# EMIF register map
Vendor: Texas Instruments
Registers are 32-bit, access per field, no defined reset value unless marked. A register's access mark holds for its fields unless they carry their own. Offsets are as the file gives them; [hi:lo] are bit positions; {n}, {i} and the like mark numbered series; 'fields as' and 'values as' point back to an identical list.

## EMIF (part 2 of 2)
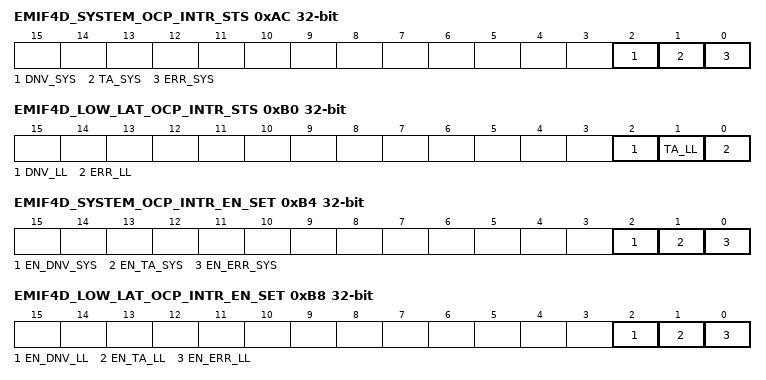
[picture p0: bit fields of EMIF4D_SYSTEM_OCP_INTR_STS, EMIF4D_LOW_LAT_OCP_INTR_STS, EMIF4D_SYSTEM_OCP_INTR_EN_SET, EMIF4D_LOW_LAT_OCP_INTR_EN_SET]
0xAC EMIF4D_SYSTEM_OCP_INTR_STS
  [2] DNV_SYS rw — Enabled status of system OCP interrupt for LPDDR2 NVM data not valid. [[br]]Write 1 to clear the status after interrupt has been serviced (raw status gets cleared, i.e. [[br]]even if not enabled). [[br]]Writing a 0 has no effect.
  [1] TA_SYS rw — Enabled status of system OCP interrupt for SDRAM temperature alert. [[br]]Write 1 to clear the status after interrupt has been serviced (raw status gets cleared, i.e. [[br]]even if not enabled). [[br]]Writing a 0 has no effect.
  [0] ERR_SYS rw — Enabled status of system OCP interrupt for command and address error. [[br]]Write 1 to clear the status after interrupt has been serviced (raw status gets cleared, i.e. [[br]]even if not enabled). [[br]]Writing a 0 has no effect.
0xB0 EMIF4D_LOW_LAT_OCP_INTR_STS
  [2] DNV_LL rw — Enabled status of low-latency OCP interrupt for LPDDR2 NVM data not valid. [[br]]Write 1 to clear the status after interrupt has been serviced (raw status gets cleared, i.e. [[br]]even if not enabled). [[br]]Writing a 0 has no effect.
  [1] TA_LL rw — Enabled status of low-latency OCP interrupt for SDRAM temperature alert. [[br]]Write 1 to clear the status after interrupt has been serviced (raw status gets cleared, i.e. [[br]]even if not enabled). [[br]]Writing a 0 has no effect.
  [0] ERR_LL rw — Enabled status of low-latency OCP interrupt for command and address error. [[br]]Write 1 to clear the status after interrupt has been serviced (raw status gets cleared, i.e. [[br]]even if not enabled). [[br]]Writing a 0 has no effect.
0xB4 EMIF4D_SYSTEM_OCP_INTR_EN_SET
  [2] EN_DNV_SYS rw — Enable set for system OCP interrupt for LPDDR2 NVM data not valid. [[br]]Writing a 1 will enable the interrupt, and set this bit as well as the corresponding Interrupt Enable Clear Register. [[br]]Writing a 0 has no effect.
  [1] EN_TA_SYS rw — Enable set for system OCP interrupt for SDRAM temperature alert. [[br]]Writing a 1 will enable the interrupt, and set this bit as well as the corresponding Interrupt Enable Clear Register. [[br]]Writing a 0 has no effect.
  [0] EN_ERR_SYS rw — Enable set for system OCP interrupt for command and address error. [[br]]Writing a 1 will enable the interrupt, and set this bit as well as the corresponding Interrupt Enable Clear Register. [[br]]Writing a 0 has no effect.
0xB8 EMIF4D_LOW_LAT_OCP_INTR_EN_SET
  [2] EN_DNV_LL rw — Enable set for low-latency OCP interrupt for LPDDR2 NVM data not valid. [[br]]Writing a 1 will enable the interrupt, and set this bit as well as the corresponding Interrupt Enable Clear Register. [[br]]Writing a 0 has no effect.
  [1] EN_TA_LL rw — Enable set for low-latency OCP interrupt for SDRAM temperature alert. [[br]]Writing a 1 will enable the interrupt, and set this bit as well as the corresponding Interrupt Enable Clear Register. [[br]]Writing a 0 has no effect.
  [0] EN_ERR_LL rw — Enable set for low-latency OCP interrupt for command and address error. [[br]]Writing a 1 will enable the interrupt, and set this bit as well as the corresponding Interrupt Enable Clear Register. [[br]]Writing a 0 has no effect.
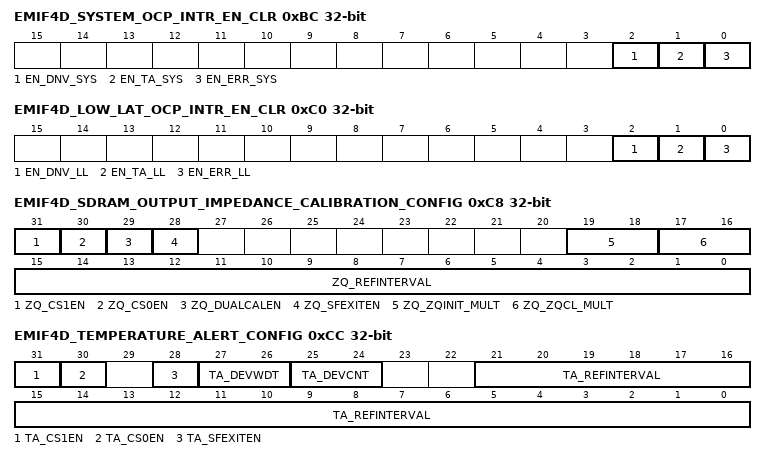
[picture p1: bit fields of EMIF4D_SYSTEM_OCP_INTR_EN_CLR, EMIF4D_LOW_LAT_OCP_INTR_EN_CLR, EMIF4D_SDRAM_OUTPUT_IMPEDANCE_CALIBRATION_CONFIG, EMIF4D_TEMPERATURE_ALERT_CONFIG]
0xBC EMIF4D_SYSTEM_OCP_INTR_EN_CLR
  [2] EN_DNV_SYS rw — Enable clear for system OCP interrupt for LPDDR2 NVM data not valid. [[br]]Writing a 1 will disable the interrupt, and clear this bit as well as the corresponding Interrupt Enable Set Register. [[br]]Writing a 0 has no effect.
  [1] EN_TA_SYS rw — Enable clear for system OCP interrupt for SDRAM temperature alert. [[br]]Writing a 1 will disable the interrupt, and clear this bit as well as the corresponding Interrupt Enable Set Register. [[br]]Writing a 0 has no effect.
  [0] EN_ERR_SYS rw — Enable clear for system OCP interrupt for command and address error. [[br]]Writing a 1 will disable the interrupt, and clear this bit as well as the corresponding Interrupt Enable Set Register. [[br]]Writing a 0 has no effect.
0xC0 EMIF4D_LOW_LAT_OCP_INTR_EN_CLR
  [2] EN_DNV_LL rw — Enable clear for low-latency OCP interrupt for LPDDR2 NVM data not valid. [[br]]Writing a 1 will disable the interrupt, and clear this bit as well as the corresponding Interrupt Enable Set Register. [[br]]Writing a 0 has no effect.
  [1] EN_TA_LL rw — Enable clear for low-latency OCP interrupt for SDRAM temperature alert. [[br]]Writing a 1 will disable the interrupt, and clear this bit as well as the corresponding Interrupt Enable Set Register. [[br]]Writing a 0 has no effect.
  [0] EN_ERR_LL rw — Enable clear for low-latency OCP interrupt for command and address error. [[br]]Writing a 1 will disable the interrupt, and clear this bit as well as the corresponding Interrupt Enable Set Register. [[br]]Writing a 0 has no effect.
0xC8 EMIF4D_SDRAM_OUTPUT_IMPEDANCE_CALIBRATION_CONFIG
  [31] ZQ_CS1EN rw — Writing a 1 enables ZQ calibration for CS1.
  [30] ZQ_CS0EN rw — Writing a 1 enables ZQ calibration for CS0.
  [29] ZQ_DUALCALEN rw — ZQ Dual Calibration enable. [[br]]Allows both ranks to be ZQ calibrated simultaneously. [[br]]Setting this bit requires both chip selects to have a seerate calibration resistor per device.
  [28] ZQ_SFEXITEN rw — ZQCL on Self Refresh, Active Power-Down, and Precharge Power-Down exit enable. [[br]]Writing a 1 enables the issuing of ZQCL on Self-Refresh, Active Power-Down, and Precharge Power-Down exit.
  [19:18] ZQ_ZQINIT_MULT rw — Indicates the number of ZQCL intervals that make up a ZQINIT interval, minus one.
  [17:16] ZQ_ZQCL_MULT rw — Indicates the number of ZQCS intervals that make up a ZQCL interval, minus one. [[br]]ZQCS interval is defined by reg_zq_zqcs in SDRAM Timing 3 Register.
  [15:0] ZQ_REFINTERVAL rw — Number of refresh periods between ZQCS commands. [[br]]This field supports between one refresh period to 256 ms between ZQCS calibration commands. [[br]]Refresh period is defined by reg_refresh_rate in SDRAM Refresh Control register.
0xCC EMIF4D_TEMPERATURE_ALERT_CONFIG
  [31] TA_CS1EN rw — Writing a 1 enables temperature alert polling for CS1.
  [30] TA_CS0EN rw — Writing a 1 enables temperature alert polling for CS0.
  [28] TA_SFEXITEN rw — Temperature Alert Poll on Self-Refresh, Active Power-Down, and Precharge Power-Down exit enable. [[br]]Writing a 1 enables the issuing of a temperature alert poll on Self-Refresh exit.
  [27:26] TA_DEVWDT rw — This field indicates how wide a physical device is. [[br]]It is used in conjunction with the reg_ta_devcnt register to determine which byte lanes contain the tempetature alert info. [[br]]A value of [[br]]0 = eight bit wide, [[br]]1 = sixteen bit wide, [[br]]2 = thirty two bit wide. [[br]]All others are reserved. [[br]]If this field is set to 1 and the reg_ta_devcnt field is set to one the byte mask for checking will be 4'b0101.
  [25:24] TA_DEVCNT rw — This field indicates which external byte lanes contain a device for temperature monitoring. [[br]]A value of [[br]]0 = one device, [[br]]1 = two devices, [[br]]2 = four devices. [[br]]All other reserved.
  [21:0] TA_REFINTERVAL rw — Number of refresh periods between temperature alert polls. [[br]]This field supports one refresh period to 10 seconds between temperature alert polls. [[br]]Refresh period is defined by reg_refresh_rate in SDRAM Refresh Control register.
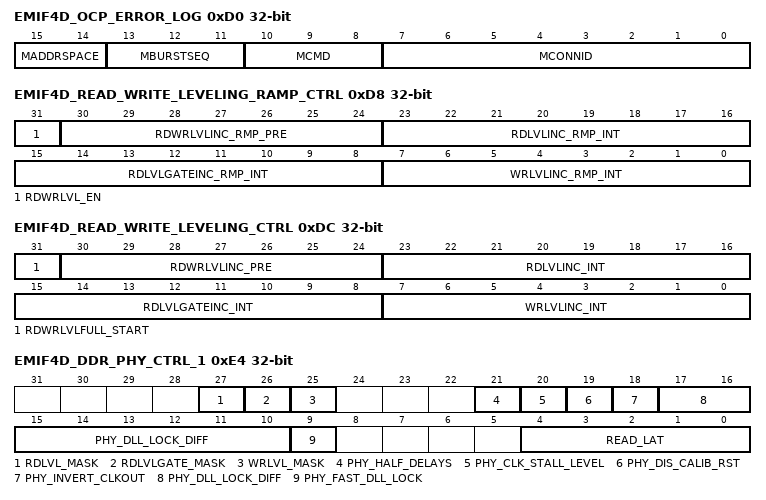
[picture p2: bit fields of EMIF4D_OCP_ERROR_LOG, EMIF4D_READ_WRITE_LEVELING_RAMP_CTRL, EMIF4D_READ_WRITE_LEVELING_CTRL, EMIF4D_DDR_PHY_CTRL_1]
0xD0 EMIF4D_OCP_ERROR_LOG ro
  [15:14] MADDRSPACE — Address space of the first errored transaction. [[br]]Writing a 1 to the lt field in the Interrupt Raw register or the lt_masked field in the Interrupt Masked register will clear this field.
  [13:11] MBURSTSEQ — Addressing mode of the first errored transaction. [[br]]Writing a 1 to the lt field in the Interrupt Raw register or the lt_masked field in the Interrupt Masked register will clear this field.
  [10:8] MCMD — Command type of the first errored transaction. [[br]]Writing a 1 to the lt field in the Interrupt Raw register or the lt_masked field in the Interrupt Masked register will clear this field.
  [7:0] MCONNID — Connection ID of the first errored transaction. [[br]]Writing a 1 to the lt field in the Interrupt Raw register or the lt_masked field in the Interrupt Masked register will clear this field.
0xD4 EMIF4D_READ_WRITE_LEVELING_RAMP_WINDOW
  [12:0] RDWRLVLINC_RMP_WIN rw — Incremental leveling ramp window in number of refresh periods. [[br]]The value programmed is minus one the required value. [[br]]Refresh period is defined by reg_refresh_rate in SDRAM Refresh Control register.
0xD8 EMIF4D_READ_WRITE_LEVELING_RAMP_CTRL rw
  [31] RDWRLVL_EN — Read-Write Leveling enable. [[br]]Set 1 to enable leveling. [[br]]Set 0 to disable leveling.
  [30:24] RDWRLVLINC_RMP_PRE — Incremental leveling pre-scalar in number of refresh periods during ramp window. [[br]]The value programmed is minus one the required value. [[br]]Refresh period is defined by reg_refresh_rate in SDRAM Refresh Control register.
  [23:16] RDLVLINC_RMP_INT — Incremental read data eye training interval during ramp window. [[br]]Number of reg_rdwrlvlinc_rmp_pre intervals between incremental read data eye training during ramp window. [[br]]A value of 0 will disable incremental read data eye training.
  [15:8] RDLVLGATEINC_RMP_INT — Incremental read DQS gate training interval during ramp window. [[br]]Number of reg_rdwrlvlinc_rmp_pre intervals between incremental read DQS gate training during ramp window. [[br]]A value of 0 will disable incremental read DQS gate training.
  [7:0] WRLVLINC_RMP_INT — Incremental write leveling interval during ramp window. [[br]]Number of reg_rdwrlvlinc_rmp_pre intervals between incremental write leveling during ramp window. [[br]]A value of 0 will disable incremental write leveling.
0xDC EMIF4D_READ_WRITE_LEVELING_CTRL rw
  [31] RDWRLVLFULL_START — Full leveling trigger. [[br]]Writing a 1 to this field triggers full read and write leveling. [[br]]This bit will self clear to 0.
  [30:24] RDWRLVLINC_PRE — Incremental leveling pre-scalar in number of refresh periods. [[br]]The value programmed is minus one the required value. [[br]]Refresh period is defined by reg_refresh_rate in SDRAM Refresh Control register.
  [23:16] RDLVLINC_INT — Incremental read data eye training interval. [[br]]Number of reg_rdwrlvlinc_pre intervals between incremental read data eye training. [[br]]A value of 0 will disable incremental read data eye training.
  [15:8] RDLVLGATEINC_INT — Incremental read DQS gate training interval. [[br]]Number of reg_rdwrlvlinc_pre intervals between incremental read DQS gate training. [[br]]A value of 0 will disable incremental read DQS gate training.
  [7:0] WRLVLINC_INT — Incremental write leveling interval. [[br]]Number of reg_rdwrlvlinc_pre intervals between incremental write leveling. [[br]]A value of 0 will disable incremental write leveling.
0xE4 EMIF4D_DDR_PHY_CTRL_1
  [27] RDLVL_MASK rw — writing a 1 to this field will mask read data eye training during full leveling command, plus drives reg_phy_use_rd_data_eye_level control low to allow user to use programmed ratio values. [[br]]Incremental training needs to be disabled using incremental training registers.
  [26] RDLVLGATE_MASK rw — writing a 1 to this field will mask dqs gate training during full leveling command, plus drives reg_phy_use_rd_dqs_level control low to allow user to use programmed ratio values. [[br]]Incremental training needs to be disabled using incremental training registers.
  [25] WRLVL_MASK rw — writing a 1 to this field will mask write leveling training during full leveling command, plus drives reg_phy_use_wr_level control low to allow user to use programmed ratio values. [[br]]Incremental training needs to be disabled using incremental training registers.
  [21] PHY_HALF_DELAYS rw — see phy spec for description
  [20] PHY_CLK_STALL_LEVEL rw — see phy spec for description
  [19] PHY_DIS_CALIB_RST rw — see phy spec for description
  [18] PHY_INVERT_CLKOUT rw — see phy spec for description
  [17:10] PHY_DLL_LOCK_DIFF rw — see phy spec for description
  [9] PHY_FAST_DLL_LOCK rw — see phy spec for description
  [4:0] READ_LAT rw — This field defines the read latency for the read data from SDRAM in number of DDR clock cycles. [[br]]This field is used by the EMIF as well as the PHY. [[br]]The EMIF will expect the first read data to arrive (reg_read_latency + 3) DDR clock cycles from the read command. [[br]]Refer to the PHY specification for information on programming this field.
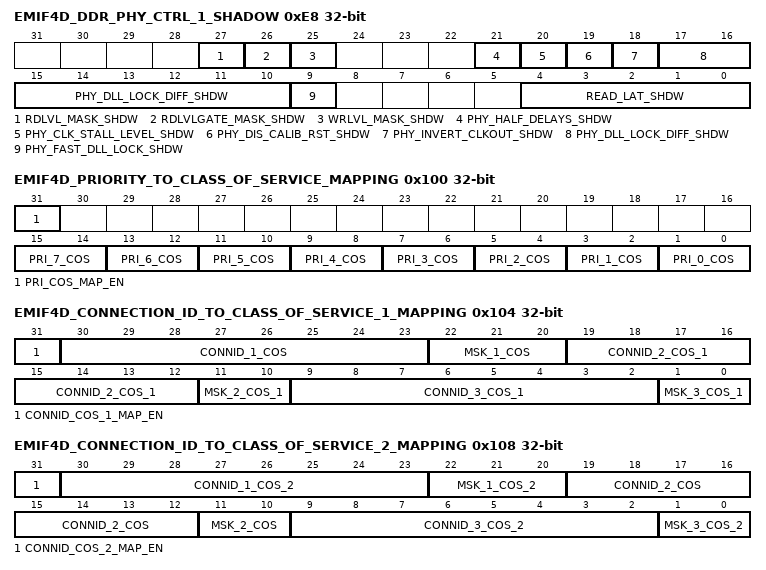
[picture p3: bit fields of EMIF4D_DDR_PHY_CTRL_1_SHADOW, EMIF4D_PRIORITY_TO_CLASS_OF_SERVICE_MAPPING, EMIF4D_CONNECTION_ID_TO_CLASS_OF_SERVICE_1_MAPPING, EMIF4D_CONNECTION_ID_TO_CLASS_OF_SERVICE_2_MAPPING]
0xE8 EMIF4D_DDR_PHY_CTRL_1_SHADOW
  [27] RDLVL_MASK_SHDW rw — writing a 1 to this field will mask read data eye training during full leveling command, plus drives reg_phy_use_rd_data_eye_level control low to allow user to use programmed ratio values. [[br]]Incremental training needs to be disabled using incremental training registers.
  [26] RDLVLGATE_MASK_SHDW rw — writing a 1 to this field will mask dqs gate training during full leveling command, plus drives reg_phy_use_rd_dqs_level control low to allow user to use programmed ratio values. [[br]]Incremental training needs to be disabled using incremental training registers.
  [25] WRLVL_MASK_SHDW rw — writing a 1 to this field will mask write leveling training during full leveling command, plus drives reg_phy_use_wr_level control low to allow user to use programmed ratio values. [[br]]Incremental training needs to be disabled using incremental training registers.
  [21] PHY_HALF_DELAYS_SHDW rw — see phy spec for description
  [20] PHY_CLK_STALL_LEVEL_SHDW rw — see phy spec for description
  [19] PHY_DIS_CALIB_RST_SHDW rw — see phy spec for description
  [18] PHY_INVERT_CLKOUT_SHDW rw — see phy spec for description
  [17:10] PHY_DLL_LOCK_DIFF_SHDW rw — see phy spec for description
  [9] PHY_FAST_DLL_LOCK_SHDW rw — see phy spec for description
  [4:0] READ_LAT_SHDW rw — Shadow field for reg_read_latency. [[br]]This field is loaded into reg_read_latency field in DDR PHY Control 1 register when SIdleAck is asserted.
0x100 EMIF4D_PRIORITY_TO_CLASS_OF_SERVICE_MAPPING
  [31] PRI_COS_MAP_EN rw — Set 1 to enable priority to class of service mapping. [[br]]Set 0 to disable mapping.
  [2n+1:2n] PRI_{n}_COS rw (n=0..7) — Class of service for commands with priority of {n}. [[br]]Value can be 1, 2, or 3. [[br]]Setting a value of 0 will have similar effects as a value of 3.
0x104 EMIF4D_CONNECTION_ID_TO_CLASS_OF_SERVICE_1_MAPPING rw
  [31] CONNID_COS_1_MAP_EN — Set 1 to enable Connection ID to class of service 1 mapping. [[br]]Set 0 to disable mapping.
  [30:23] CONNID_1_COS — Connection ID value 1 for class of service 1.
  [22:20] MSK_1_COS — Mask for Connection ID value 1 for class of service 1. [[br]]Value of 0 will disable masking. [[br]]Value of 1 will mask Connection ID bit 0. [[br]]Value of 2 will mask Connection ID bits [[br]]1:0. [[br]]Value of 3 will mask Connection ID bits [[br]]2:0. [[br]]Value of 4 will mask Connection ID bits [[br]]3:0. [[br]]Value of 5 will mask Connection ID bits [[br]]4:0. [[br]]Value of 6 will mask Connection ID bits [[br]]5:0. [[br]]Value of 7 will mask Connection ID bits [[br]]6:0.
  [19:12] CONNID_2_COS_1 — Connection ID value 2 for class of service 1.
  [11:10] MSK_2_COS_1 — Mask for Connection ID value 2 for class of service 1. [[br]]Value of 0 will disable masking. [[br]]Value of 1 will mask Connection ID bit 0. [[br]]Value of 2 will mask Connection ID bits [[br]]1:0. [[br]]Value of 3 will mask Connection ID bits [[br]]2:0.
  [9:2] CONNID_3_COS_1 — Connection ID value 3 for class of service 1.
  [1:0] MSK_3_COS_1 — Mask for Connection ID value 3 for class of service 1. [[br]]Value of 0 will disable masking. [[br]]Value of 1 will mask Connection ID bit 0. [[br]]Value of 2 will mask Connection ID bits [[br]]1:0. [[br]]Value of 3 will mask Connection ID bits [[br]]2:0.
0x108 EMIF4D_CONNECTION_ID_TO_CLASS_OF_SERVICE_2_MAPPING rw
  [31] CONNID_COS_2_MAP_EN — Set 1 to enable Connection ID to class of service 2 mapping. [[br]]Set 0 to disable mapping.
  [30:23] CONNID_1_COS_2 — Connection ID value 1 for class of service 2.
  [22:20] MSK_1_COS_2 — Mask for Connection ID value 1 for class of service 2. [[br]]Value of 0 will disable masking. [[br]]Value of 1 will mask Connection ID bit 0. [[br]]Value of 2 will mask Connection ID bits [[br]]1:0. [[br]]Value of 3 will mask Connection ID bits [[br]]2:0. [[br]]Value of 4 will mask Connection ID bits [[br]]3:0. [[br]]Value of 5 will mask Connection ID bits [[br]]4:0. [[br]]Value of 6 will mask Connection ID bits [[br]]5:0. [[br]]Value of 7 will mask Connection ID bits [[br]]6:0.
  [19:12] CONNID_2_COS — Connection ID value 2 for class of service 2.
  [11:10] MSK_2_COS — Mask for Connection ID value 2 for class of service 2. [[br]]Value of 0 will disable masking. [[br]]Value of 1 will mask Connection ID bit 0. [[br]]Value of 2 will mask Connection ID bits [[br]]1:0. [[br]]Value of 3 will mask Connection ID bits [[br]]2:0.
  [9:2] CONNID_3_COS_2 — Connection ID value 3 for class of service 2.
  [1:0] MSK_3_COS_2 — Mask for Connection ID value 3 for class of service 2. [[br]]Value of 0 will disable masking. [[br]]Value of 1 will mask Connection ID bit 0. [[br]]Value of 2 will mask Connection ID bits [[br]]1:0. [[br]]Value of 3 will mask Connection ID bits [[br]]2:0.
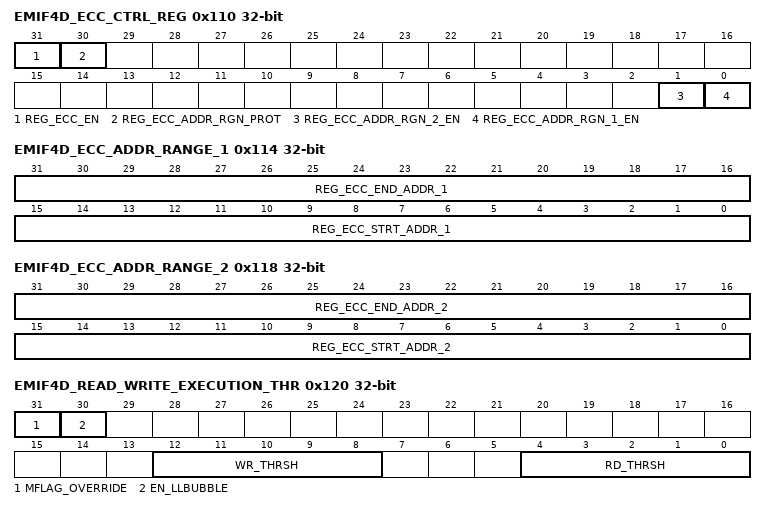
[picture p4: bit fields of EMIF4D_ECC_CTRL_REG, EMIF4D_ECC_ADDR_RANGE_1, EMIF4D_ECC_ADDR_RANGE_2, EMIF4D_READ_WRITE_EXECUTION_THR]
0x110 EMIF4D_ECC_CTRL_REG
  [31] REG_ECC_EN rw — Set 1 to enable ECC. [[br]]Set 0 to disable ECC.
  [30] REG_ECC_ADDR_RGN_PROT rw — Setting this field to 1 and reg_ecc_en to a 1 will enable ECC calculation for accesses within the address ranges and disable ECC calculation for accesses outside the address ranges. [[br]]Setting this field to 0 and reg_ecc_en to a 1 will disable ECC calculation for accesses within the address ranges and enable ECC calculation for accesses outside the address ranges. [[br]]The address ranges can be specified using the ECC Address Range 1 and 2 registers.
  [1] REG_ECC_ADDR_RGN_2_EN rw — Set 1 to enable ECC address range 2. [[br]]Set 0 to disable ECC address range 2.
  [0] REG_ECC_ADDR_RGN_1_EN rw — Set 1 to enable ECC address range 1. [[br]]Set 0 to disable ECC address range 1.
0x114 EMIF4D_ECC_ADDR_RANGE_1 rw
  [31:16] REG_ECC_END_ADDR_1 — End caddress[[br]][32:17] for ECC address range 1
  [15:0] REG_ECC_STRT_ADDR_1 — Start caddress[[br]][32:17] for ECC address range 1
0x118 EMIF4D_ECC_ADDR_RANGE_2 rw
  [31:16] REG_ECC_END_ADDR_2 — End caddress[[br]][32:17] for ECC address range 2
  [15:0] REG_ECC_STRT_ADDR_2 — Start caddress[[br]][32:17] for ECC address range 2
0x120 EMIF4D_READ_WRITE_EXECUTION_THR
  [31] MFLAG_OVERRIDE rw — [[br]]0 = Use MFLAG, [[br]]1 = Use Class of Service
  [30] EN_LLBUBBLE rw — [[br]]0 = No LL Bubble, [[br]]1 = LL Bubble Enabled.
  [12:8] WR_THRSH rw — Write Threshold. [[br]]Number of SDRAM write bursts after which the EMIF arbitration will switch to executing read commands. [[br]]The value programmed is always minus one the required number.
  [4:0] RD_THRSH rw — Read Threshold. [[br]]Number of SDRAM read bursts after which the EMIF arbitration will switch to executing write commands. [[br]]The value programmed is always minus one the required number.
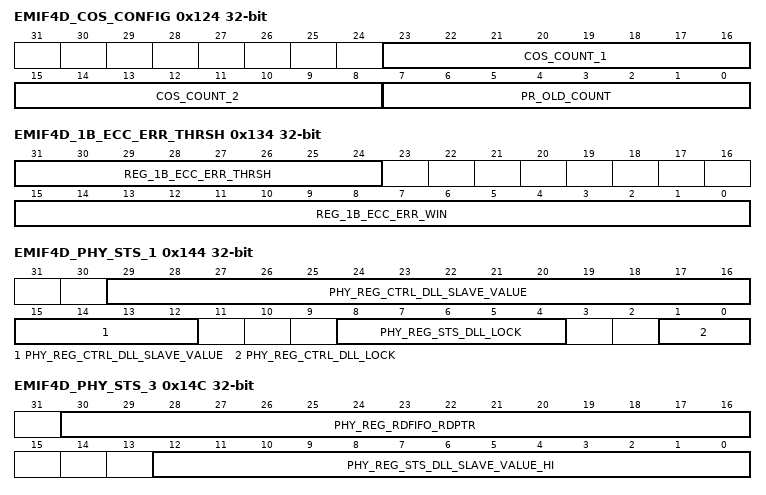
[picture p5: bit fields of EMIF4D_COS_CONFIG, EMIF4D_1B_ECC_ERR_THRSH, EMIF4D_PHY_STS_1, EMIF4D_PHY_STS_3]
0x124 EMIF4D_COS_CONFIG
  [23:16] COS_COUNT_1 rw — Priority Raise Counter for class of service 1. [[br]]Number of m_clk cycles after which the EMIF momentarily raises the priority of the class of service 1 commands in the Command FIFO. [[br]]A value of N will be equal to N x 16 clocks.
  [15:8] COS_COUNT_2 rw — Priority Raise Counter for class of service 2. [[br]]Number of m_clk cycles after which the EMIF momentarily raises the priority of the class of service 2 commands in the Command FIFO. [[br]]A value of N will be equal to N x 16 clocks.
  [7:0] PR_OLD_COUNT rw — Priority Raise Old Counter. [[br]]Number of m_clk cycles after which the EMIF momentarily raises the priority of the oldest command in the Command FIFO. [[br]]A value of N will be equal to N x 16 clocks.
0x130 EMIF4D_1B_ECC_ERR_CNT rw
  [31:0] REG_1B_ECC_ERR_CNT — 32 bit counter that displays number of 1 bit ECC errors. [[br]]Writing a value will decrement the count by that value. [[br]]For example, if the count is 0x1234_ABF3, writing 0x1234_ABF3 to this register will clear it.
0x134 EMIF4D_1B_ECC_ERR_THRSH
  [31:24] REG_1B_ECC_ERR_THRSH rw — 1 bit ECC error threshold. [[br]]The EMIF will generate an interrupt when the 1 bit ECC error count is greater than or equal to this threshold. [[br]]A value of 0 will disable the generation of the interrupt.
  [15:0] REG_1B_ECC_ERR_WIN rw — 1 bit ECC error window in number of refresh periods. [[br]]The EMIF will generate an interrupt when the 1 bit ECC error count is equal to or greater than the threshold within this window. [[br]]A value of 0 will disable the window. [[br]]Refresh period is defined by reg_refresh_rate in SDRAM Refresh Control register. [[br]]The software can set this bitfield to 0x0 to reset the internal counter.
0x138 EMIF4D_1B_ECC_ERR_DIST_1 rw
  [31:0] REG_1B_ECC_ERR_DIST_1 — 1 bit ECC error distribution over data bus bit 31:0. [[br]]A value of 1 on a bit indicates 1 bit error on the corresponding bit on the data bus. [[br]]Writing a 1 to any bit will clear that bit. [[br]]Writing a 0 has no effect.
0x13C EMIF4D_1B_ECC_ERR_ADDR_LOG rw
  [31:0] REG_1B_ECC_ERR_ADDR — 1 bit ECC error address. [[br]]Most significant bits of the starting address(es) related to the SDRAM reads that had a 1 bit ECC error. [[br]]This field displays up to four addresses logged in the 4 deep address logging FIFO. [[br]]Writing a 0x1 will pop one element of the FIFO. [[br]]Writing a 0x2 will pop all elements of the FIFO. [[br]]Writing any other alue will have no effect.
0x140 EMIF4D_2B_ECC_ERR_ADDR_LOG rw
  [31:0] REG_2B_ECC_ERR_ADDR — 2 bit ECC error address. [[br]]Most significant bits of the starting address of the first SDRAM burst that had the 2 bit ECC error. [[br]]Writing a 1 will clear this field. [[br]]Writing any other value has no effect.
0x144 EMIF4D_PHY_STS_1 ro
  [29:12] PHY_REG_CTRL_DLL_SLAVE_VALUE — DLL Slave Value
  [8:4] PHY_REG_STS_DLL_LOCK — Lock Status for Data DLLs
  [1:0] PHY_REG_CTRL_DLL_LOCK — Lock Status for Command DLLs
0x148 EMIF4D_PHY_STS_2 ro
  [31:0] PHY_REG_STS_DLL_SLAVE_VALUE_LO — Bits 31:0 of Phy_reg_status_dll_slave_value
0x14C EMIF4D_PHY_STS_3 ro
  [30:16] PHY_REG_RDFIFO_RDPTR — Read FIFO Read Pointer
  [12:0] PHY_REG_STS_DLL_SLAVE_VALUE_HI — Bits [[br]]44:32 of Phy_reg_status_dll_slave_value
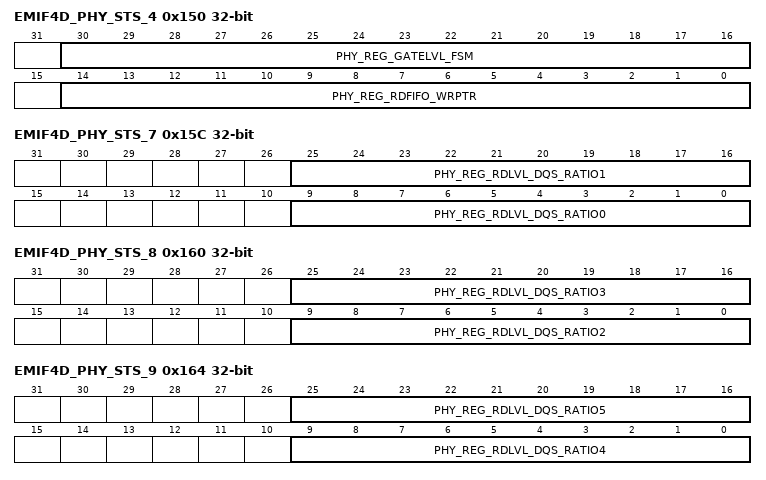
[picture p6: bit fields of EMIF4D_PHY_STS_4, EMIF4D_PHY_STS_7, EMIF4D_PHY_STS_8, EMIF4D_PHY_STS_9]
0x150 EMIF4D_PHY_STS_4 ro
  [30:16] PHY_REG_GATELVL_FSM — Gate Levelling FSM
  [14:0] PHY_REG_RDFIFO_WRPTR — Read FIFO Write Pointer
0x154 EMIF4D_PHY_STS_5 ro
  [19:0] PHY_REG_RD_LEVEL_FSM — Read Levelling FSM
0x158 EMIF4D_PHY_STS_6 ro
  [14:0] PHY_REG_WR_LEVEL_FSM — Writel Levelling FSM
0x15C EMIF4D_PHY_STS_7 ro
  [25:16] PHY_REG_RDLVL_DQS_RATIO1 — Read levelling DQS ratio1
  [9:0] PHY_REG_RDLVL_DQS_RATIO0 — Read levelling DQS ratio0
0x160 EMIF4D_PHY_STS_8 ro
  [25:16] PHY_REG_RDLVL_DQS_RATIO3 — Read levelling DQS ratio3
  [9:0] PHY_REG_RDLVL_DQS_RATIO2 — Read levelling DQS ratio2
0x164 EMIF4D_PHY_STS_9 ro
  [25:16] PHY_REG_RDLVL_DQS_RATIO5 — Read Levelling DQS ratio5
  [9:0] PHY_REG_RDLVL_DQS_RATIO4 — Read Levelling DQS ratio4
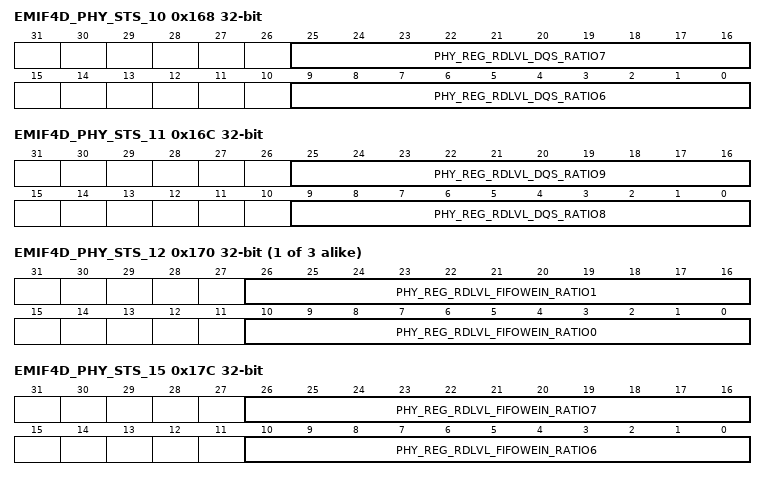
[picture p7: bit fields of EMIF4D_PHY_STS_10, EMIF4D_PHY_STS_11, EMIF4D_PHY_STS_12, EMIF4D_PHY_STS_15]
0x168 EMIF4D_PHY_STS_10 ro
  [25:16] PHY_REG_RDLVL_DQS_RATIO7 — Read levelling DQS ratio7
  [9:0] PHY_REG_RDLVL_DQS_RATIO6 — Read levelling DQS ratio6
0x16C EMIF4D_PHY_STS_11 ro
  [25:16] PHY_REG_RDLVL_DQS_RATIO9 — Read levelling DQS ratio9
  [9:0] PHY_REG_RDLVL_DQS_RATIO8 — Read levelling DQS ratio8
{0x140+4i} EMIF4D_PHY_STS_{i} ro (i=12..14)
  [26:16] PHY_REG_RDLVL_FIFOWEIN_RATIO{2i-23} — Read levelling FIFO Write Enable Ratio{2i-23}
  [10:0] PHY_REG_RDLVL_FIFOWEIN_RATIO{2i-24} — Read levelling FIFO Write Enable Ratio{2i-24}
0x17C EMIF4D_PHY_STS_15 ro
  [26:16] PHY_REG_RDLVL_FIFOWEIN_RATIO7 — Read levelling FIFO Wrie Enable Ratio7
  [10:0] PHY_REG_RDLVL_FIFOWEIN_RATIO6 — Read levelling FIFO Wrie Enable Ratio6
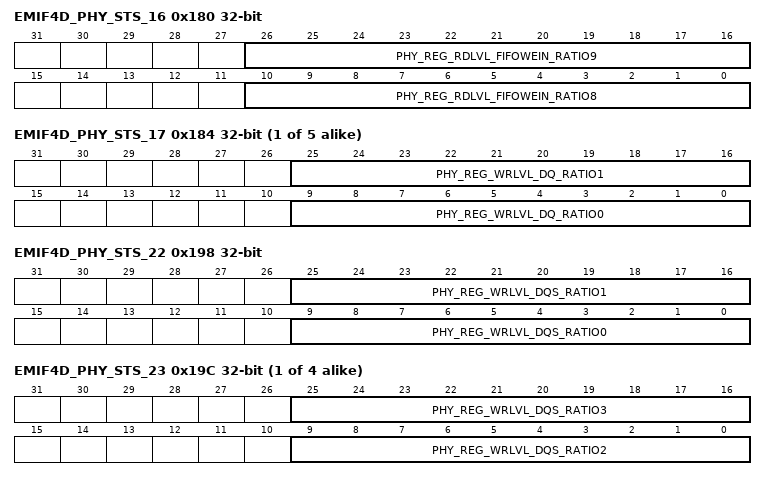
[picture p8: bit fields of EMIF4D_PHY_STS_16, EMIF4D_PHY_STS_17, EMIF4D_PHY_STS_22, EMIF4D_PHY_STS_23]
0x180 EMIF4D_PHY_STS_16 ro
  [26:16] PHY_REG_RDLVL_FIFOWEIN_RATIO9 — Read levelling FIFO Write Enable Ratio9
  [10:0] PHY_REG_RDLVL_FIFOWEIN_RATIO8 — Read levelling FIFO Write Enable Ratio8
{0x140+4i} EMIF4D_PHY_STS_{i} ro (i=17..21)
  [25:16] PHY_REG_WRLVL_DQ_RATIO{2i-33} — Write levelling DQ ratio{2i-33}
  [9:0] PHY_REG_WRLVL_DQ_RATIO{2i-34} — Write levelling DQ ratio{2i-34}
0x198 EMIF4D_PHY_STS_22 ro
  [25:16] PHY_REG_WRLVL_DQS_RATIO1 — Write levelling DQS ratio 1
  [9:0] PHY_REG_WRLVL_DQS_RATIO0 — Write levelling DQS ratio 0
{0x140+4i} EMIF4D_PHY_STS_{i} ro (i=23..26)
  [25:16] PHY_REG_WRLVL_DQS_RATIO{2i-43} — Write levelling DQS ratio{2i-43}
  [9:0] PHY_REG_WRLVL_DQS_RATIO{2i-44} — Write levelling DQS ratio{2i-44}
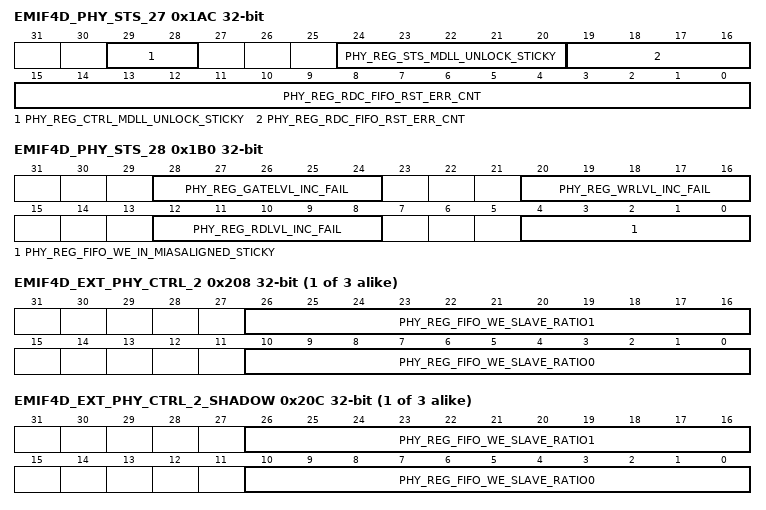
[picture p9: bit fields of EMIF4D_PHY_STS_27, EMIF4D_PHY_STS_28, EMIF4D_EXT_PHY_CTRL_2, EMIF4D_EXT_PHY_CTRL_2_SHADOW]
0x1AC EMIF4D_PHY_STS_27 ro
  [29:28] PHY_REG_CTRL_MDLL_UNLOCK_STICKY — Phy control MDLL unlock sticky
  [24:20] PHY_REG_STS_MDLL_UNLOCK_STICKY — Phy data MDLL unlock sticky
  [19:0] PHY_REG_RDC_FIFO_RST_ERR_CNT — RDC FIFO reset error count
0x1B0 EMIF4D_PHY_STS_28 ro
  [28:24] PHY_REG_GATELVL_INC_FAIL — Gate levelling failure
  [20:16] PHY_REG_WRLVL_INC_FAIL — Write levelling failure
  [12:8] PHY_REG_RDLVL_INC_FAIL — Read levelling failure
  [4:0] PHY_REG_FIFO_WE_IN_MIASALIGNED_STICKY — FIFO write enable in misaligned stickly
0x200 EMIF4D_EXT_PHY_CTRL_1
  [29:0] PHY_REG_CTRL_SLAVE_RATIO rw — Ctrl Slave Ratio
0x204 EMIF4D_EXT_PHY_CTRL_1_SHADOW
  [29:0] PHY_REG_CTRL_SLAVE_RATIO rw — Ctrl Slave Ratio
{0x1F8+8i} EMIF4D_EXT_PHY_CTRL_{i} (i=2..4)
  [26:16] PHY_REG_FIFO_WE_SLAVE_RATIO{2i-3} rw — FIFO write enable slave ratio{2i-3}
  [10:0] PHY_REG_FIFO_WE_SLAVE_RATIO{2i-4} rw — FIFO write enable slave ratio{2i-4}
{0x1FC+8i} EMIF4D_EXT_PHY_CTRL_{i}_SHADOW (i=2..4)
  fields as EMIF4D_EXT_PHY_CTRL_2
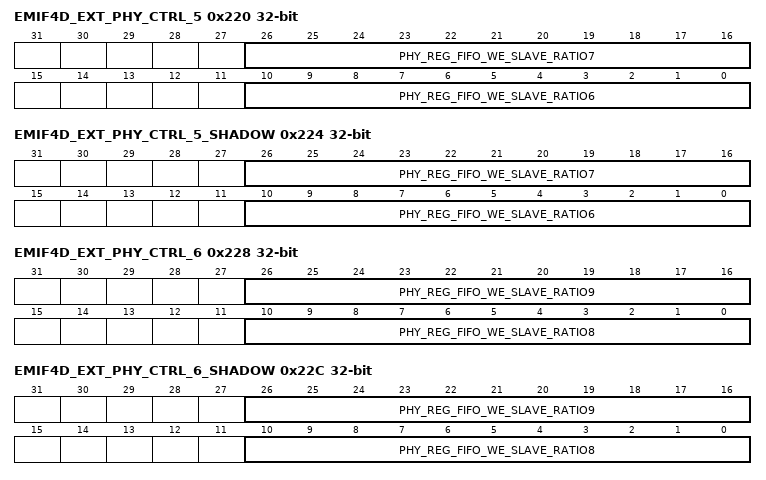
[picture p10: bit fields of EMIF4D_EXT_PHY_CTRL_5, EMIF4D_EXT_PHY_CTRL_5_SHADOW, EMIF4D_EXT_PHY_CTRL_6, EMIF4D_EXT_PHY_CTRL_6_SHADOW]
0x220 EMIF4D_EXT_PHY_CTRL_5
  [26:16] PHY_REG_FIFO_WE_SLAVE_RATIO7 rw — FIFO wrie enable slave ratio7
  [10:0] PHY_REG_FIFO_WE_SLAVE_RATIO6 rw — FIFO wrie enable slave ratio6
0x224 EMIF4D_EXT_PHY_CTRL_5_SHADOW
  fields as EMIF4D_EXT_PHY_CTRL_5
0x228 EMIF4D_EXT_PHY_CTRL_6
  [26:16] PHY_REG_FIFO_WE_SLAVE_RATIO9 rw — FIFO write enable slave ratio9
  [10:0] PHY_REG_FIFO_WE_SLAVE_RATIO8 rw — FIFO write enable slave ratio8
0x22C EMIF4D_EXT_PHY_CTRL_6_SHADOW
  fields as EMIF4D_EXT_PHY_CTRL_6
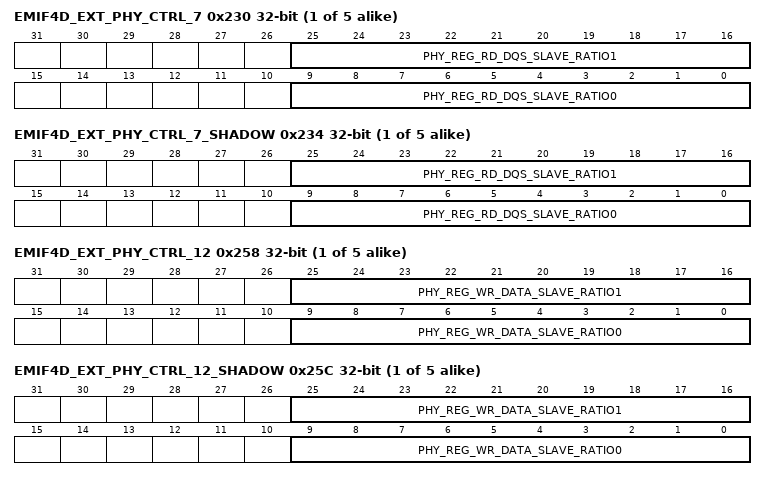
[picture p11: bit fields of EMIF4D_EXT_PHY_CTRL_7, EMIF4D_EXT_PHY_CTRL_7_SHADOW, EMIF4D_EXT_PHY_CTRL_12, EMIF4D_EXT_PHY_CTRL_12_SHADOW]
{0x1F8+8i} EMIF4D_EXT_PHY_CTRL_{i} (i=7..11)
  [25:16] PHY_REG_RD_DQS_SLAVE_RATIO{2i-13} rw — Read DQS Slave Ratio{2i-13}
  [9:0] PHY_REG_RD_DQS_SLAVE_RATIO{2i-14} rw — Read DQS Slave Ratio{2i-14}
{0x1FC+8i} EMIF4D_EXT_PHY_CTRL_{i}_SHADOW (i=7..11)
  fields as EMIF4D_EXT_PHY_CTRL_7
{0x1F8+8i} EMIF4D_EXT_PHY_CTRL_{i} (i=12..16)
  [25:16] PHY_REG_WR_DATA_SLAVE_RATIO{2i-23} rw — Write Data Slave Ratio{2i-23}
  [9:0] PHY_REG_WR_DATA_SLAVE_RATIO{2i-24} rw — Write Data Slave Ratio{2i-24}
{0x1FC+8i} EMIF4D_EXT_PHY_CTRL_{i}_SHADOW (i=12..16)
  fields as EMIF4D_EXT_PHY_CTRL_12
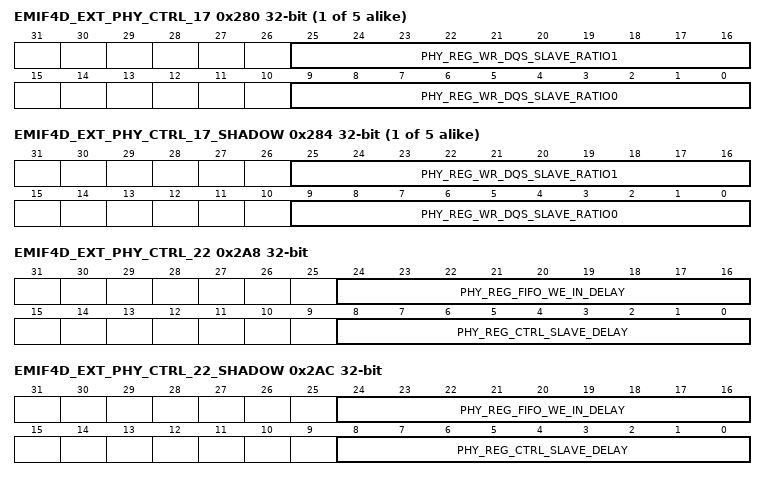
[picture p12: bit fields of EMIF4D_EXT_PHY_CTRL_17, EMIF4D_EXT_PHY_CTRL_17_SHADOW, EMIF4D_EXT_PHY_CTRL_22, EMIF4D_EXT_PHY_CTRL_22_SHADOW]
{0x1F8+8i} EMIF4D_EXT_PHY_CTRL_{i} (i=17..21)
  [25:16] PHY_REG_WR_DQS_SLAVE_RATIO{2i-33} rw — Write Data Slave Ratio{2i-33}
  [9:0] PHY_REG_WR_DQS_SLAVE_RATIO{2i-34} rw — Write Data Slave Ratio{2i-34}
{0x1FC+8i} EMIF4D_EXT_PHY_CTRL_{i}_SHADOW (i=17..21)
  fields as EMIF4D_EXT_PHY_CTRL_17
0x2A8 EMIF4D_EXT_PHY_CTRL_22
  [24:16] PHY_REG_FIFO_WE_IN_DELAY rw — FIFO write enable in delay
  [8:0] PHY_REG_CTRL_SLAVE_DELAY rw — Ctrl slave delay
0x2AC EMIF4D_EXT_PHY_CTRL_22_SHADOW
  fields as EMIF4D_EXT_PHY_CTRL_22
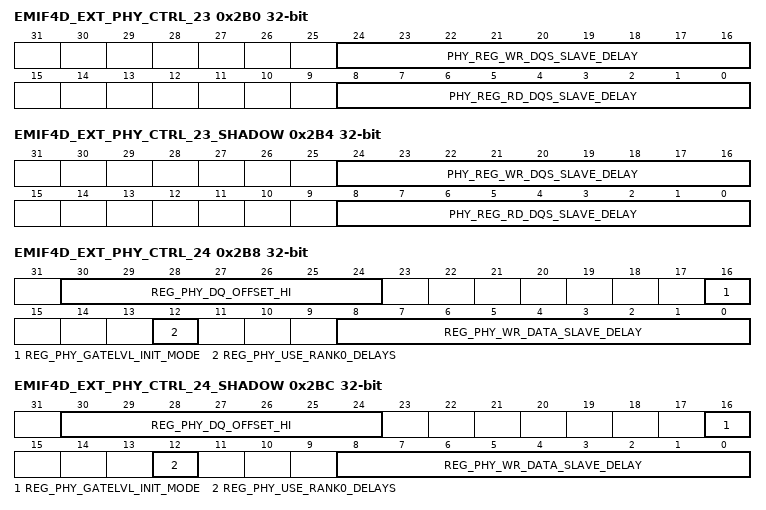
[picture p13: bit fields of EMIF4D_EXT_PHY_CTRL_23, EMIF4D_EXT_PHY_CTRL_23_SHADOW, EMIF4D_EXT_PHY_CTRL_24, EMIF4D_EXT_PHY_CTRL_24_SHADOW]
0x2B0 EMIF4D_EXT_PHY_CTRL_23
  [24:16] PHY_REG_WR_DQS_SLAVE_DELAY rw — Write DQS Slave delay
  [8:0] PHY_REG_RD_DQS_SLAVE_DELAY rw — Read DQS Slave delay
0x2B4 EMIF4D_EXT_PHY_CTRL_23_SHADOW
  fields as EMIF4D_EXT_PHY_CTRL_23
0x2B8 EMIF4D_EXT_PHY_CTRL_24
  [30:24] REG_PHY_DQ_OFFSET_HI rw — Phy DQ Offset bits [[br]]34:28
  [16] REG_PHY_GATELVL_INIT_MODE rw — Gate levelling init mode
  [12] REG_PHY_USE_RANK0_DELAYS rw — Use rank0 delays
  [8:0] REG_PHY_WR_DATA_SLAVE_DELAY rw — Wirte data slave delay
0x2BC EMIF4D_EXT_PHY_CTRL_24_SHADOW
  fields as EMIF4D_EXT_PHY_CTRL_24
0x2C0 EMIF4D_EXT_PHY_CTRL_25
  [27:0] REG_PHY_DQ_OFFSET rw — DQ offset
0x2C4 EMIF4D_EXT_PHY_CTRL_25_SHADOW
  [27:0] REG_PHY_DQ_OFFSET rw — DQ offset
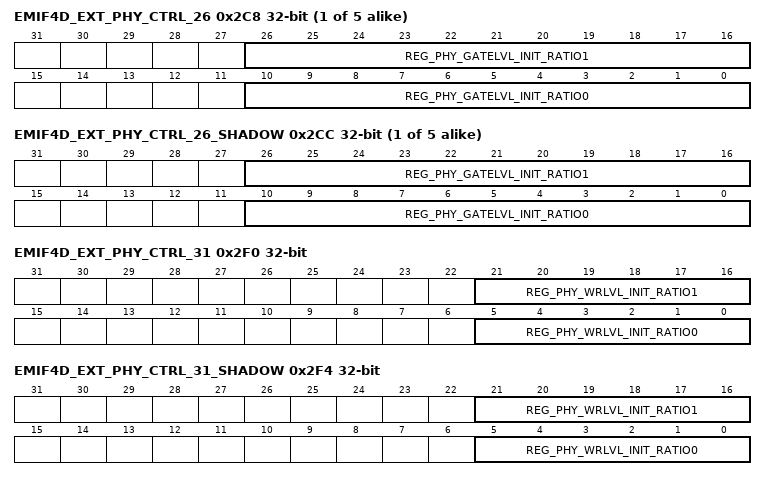
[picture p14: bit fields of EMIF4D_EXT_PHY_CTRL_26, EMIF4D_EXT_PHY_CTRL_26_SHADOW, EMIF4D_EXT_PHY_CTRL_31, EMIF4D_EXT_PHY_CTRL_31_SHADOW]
{0x1F8+8i} EMIF4D_EXT_PHY_CTRL_{i} (i=26..30)
  [26:16] REG_PHY_GATELVL_INIT_RATIO{2i-51} rw — Gate levelling init ratio{2i-51}
  [10:0] REG_PHY_GATELVL_INIT_RATIO{2i-52} rw — Gate levelling init ratio{2i-52}
{0x1FC+8i} EMIF4D_EXT_PHY_CTRL_{i}_SHADOW (i=26..30)
  fields as EMIF4D_EXT_PHY_CTRL_26
0x2F0 EMIF4D_EXT_PHY_CTRL_31
  [21:16] REG_PHY_WRLVL_INIT_RATIO1 rw — Write levelling init ratio1
  [5:0] REG_PHY_WRLVL_INIT_RATIO0 rw — Write levelling init ratio0
0x2F4 EMIF4D_EXT_PHY_CTRL_31_SHADOW
  fields as EMIF4D_EXT_PHY_CTRL_31
{0x1F8+8i} EMIF4D_EXT_PHY_CTRL_{i} (i=32..35)
  [25:16] REG_PHY_WRLVL_INIT_RATIO{2i-61} rw — Write levelling init ratio{2i-61}
  [9:0] REG_PHY_WRLVL_INIT_RATIO{2i-62} rw — Write levelling init ratio{2i-62}
{0x1FC+8i} EMIF4D_EXT_PHY_CTRL_{i}_SHADOW (i=32..35)
  fields as EMIF4D_EXT_PHY_CTRL_32
0x318 EMIF4D_EXT_PHY_CTRL_36
  [10] REG_PHY_RDC_FIFO_RST_ERR_CNT_CLR rw — RDC FIFO Reset Error Count Clear
  [9] REG_PHY_MDLL_UNLOCK_CLR rw — MDLL Unlock Clear
  [8] REG_PHY_FIFO_WE_IN_MISALIGNED_CLR rw — FIFO Write Enable In Misaligned Clear
  [7:4] REG_PHY_WRLVL_NUM_OF_DQ0 rw — Write levelling number of DQ0
  [3:0] REG_PHY_GATELVL_NUM_OF_DQ0 rw — Gate levelling number of DQ0
0x31C EMIF4D_EXT_PHY_CTRL_36_SHADOW
  fields as EMIF4D_EXT_PHY_CTRL_36
